# STM32G0C1 register map
File version: 1.0
CPU: CM0 r0p1, little endian, MPU, no FPU, 4 interrupt priority bits
Registers are 32-bit, read-write, reset 0x0 unless marked. A register's access mark holds for its fields unless they carry their own. Offsets are from the block's base; lines under a group give offsets from that group; [hi:lo] are bit positions; {n}, {i} and the like mark numbered series; 'fields as' and 'values as' point back to an identical list; <NAME> marks a mode.

## Memory map
0x40000000 TIM2 size 0x400 — General-purpose-timers
0x40000400 TIM3 size 0x400
0x40001000 TIM6 size 0x400 — Basic timers
0x40001400 TIM7 size 0x400
0x40002000 TIM14 size 0x400 — General purpose timers
0x40002C00 WWDG size 0x400 — System window watchdog
0x40003000 IWDG size 0x400 — Independent watchdog
0x40004400 USART2 size 0x400
0x40004800 USART3 size 0x400
0x40004C00 USART4 size 0x400
0x40005400 I2C1 size 0x400 — Inter-integrated circuit
0x40005800 I2C2 size 0x400
0x40007400 DAC size 0x400
0x40007800 HDMI_CEC size 0x400
0x40007C00 LPTIM1 size 0x400 — Low power timer
0x40009400 LPTIM2 size 0x400
0x40010030 VREFBUF size 0x400 — System configuration controller
0x40012C00 TIM1 size 0x400 — Advanced-timers
0x40013800 USART1 size 0x400 — Universal synchronous asynchronous receiver transmitter
0x40014000 TIM15 size 0x400 — General purpose timers
0x40014400 TIM16 size 0x400 — General purpose timers
0x40014800 TIM17 size 0x400
0x40020800 DMAMUX size 0x800
0x40023000 CRC size 0x400 — Cyclic redundancy check calculation unit

## Interrupts
0 WWDG — Window watchdog interrupt
11 DMA_Channel4_5_6_7 (DMAMUX) — DMA channel 4, 5, 6 & 7 and DMAMUX
13 TIM1_BRK_UP_TRG_COM (TIM1) — TIM1 break, update, trigger
14 TIM1_CC (TIM1) — TIM1 Capture Compare interrupt
15 TIM2 — TIM2 global interrupt
16 TIM3 — TIM3 global interrupt
17 TIM6_DAC (TIM6) — TIM6 + LPTIM1 and DAC global interrupt
18 TIM7 — TIM7 + LPTIM2 global interrupt
19 TIM14 — TIM14 global interrupt
20 TIM15 — Timer 15 global interrupt
21 TIM16 — TIM16 global interrupt
22 TIM17 — TIM17 global interrupt
23 I2C1 — I2C1 global interrupt
24 I2C2 — I2C2 global interrupt
27 USART1 — USART1 global interrupt
28 USART2 — USART2 global interrupt
29 USART3_USART4_LPUART1 (USART3) — USART3, USART4, and LPUART1 global interrupt
30 CEC (HDMI_CEC) — CEC global interrupt

## CRC — Cyclic redundancy check calculation unit
Base 0x40023000
0x00 CRC_DR reset 0xFFFFFFFF — Data register
  [31:0] DR — Data register bits
0x04 CRC_IDR — Independent data register
  [31:0] IDR — General-purpose 32-bit data register bits
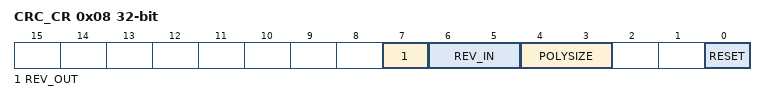
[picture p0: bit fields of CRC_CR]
0x08 CRC_CR access per field — Control register
  [7] REV_OUT rw — Reverse output data This bit controls the reversal of the bit order of the output data.
    0=Bit order not affected; 1=Bit-reversed output format
  [6:5] REV_IN rw — Reverse input data These bits control the reversal of the bit order of the input data
    0=Bit order not affected; 1=Bit reversal done by byte; 2=Bit reversal done by half-word; 3=Bit reversal done by word
  [4:3] POLYSIZE rw — Polynomial size These bits control the size of the polynomial.
    0=32 bit polynomial; 1=16 bit polynomial; 2=8 bit polynomial; 3=7 bit polynomial
  [0] RESET wo — RESET bit
0x10 CRC_INIT reset 0xFFFFFFFF — Initial CRC value
  [31:0] CRC_INIT — Programmable initial CRC value
0x14 CRC_POL reset 0x4C11DB7 — polynomial
  [31:0] POL — Programmable polynomial

## DMAMUX
Base 0x40020800
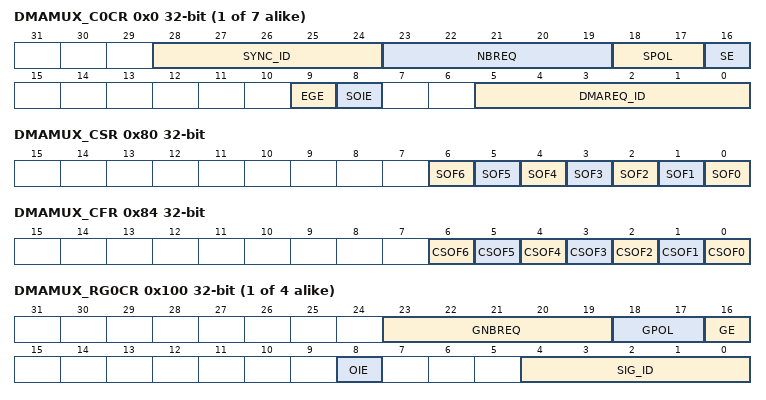
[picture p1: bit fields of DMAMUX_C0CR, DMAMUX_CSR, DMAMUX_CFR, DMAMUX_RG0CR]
{0x0+4i} DMAMUX_C{i}CR (i=0..6) — DMAMUX request line multiplexer channel x configuration register
  [28:24] SYNC_ID — Synchronization identification Selects the synchronization input (see inputs to resources STM32G0).
  [23:19] NBREQ — Number of DMA requests minus 1 to forward Defines the number of DMA requests to forward to the DMA controller after a synchronization event, and/or the number of DMA requests before an output event is generated. This field shall only be written when both SE and EGE bits are low.
  [18:17] SPOL — Synchronization polarity Defines the edge polarity of the selected synchronization input:
    0=no event, i.e. no synchronization nor detection.; 1=rising edge; 2=falling edge; 3=rising and falling edge
  [16] SE — Synchronization enable
    0=synchronization disabled; 1=synchronization enabled
  [9] EGE — Event generation enable
    0=event generation disabled; 1=event generation enabled
  [8] SOIE — Synchronization overrun interrupt enable
    0=interrupt disabled; 1=interrupt enabled
  [5:0] DMAREQ_ID — DMA request identification Selects the input DMA request. See the DMAMUX table about assignments of multiplexer inputs to resources.
0x80 DMAMUX_CSR ro — DMAMUX request line multiplexer interrupt channel status register
  [n] SOF{n} (n=0..6) — Synchronization overrun event flag The flag is set when a synchronization event occurs on a DMA request line multiplexer channel x, while the DMA request counter value is lower than NBREQ. The flag is cleared by writing 1 to the corresponding CSOFx bit in DMAMUX_CFR register.
0x84 DMAMUX_CFR wo — DMAMUX request line multiplexer interrupt clear flag register
  [n] CSOF{n} (n=0..6) — Clear synchronization overrun event flag Writing 1 in each bit clears the corresponding overrun flag SOFx in the DMAMUX_CSR register.
{0x100+4i} DMAMUX_RG{i}CR (i=0..3) — DMAMUX request generator channel x configuration register
  [23:19] GNBREQ — Number of DMA requests to be generated (minus 1) Defines the number of DMA requests to be generated after a trigger event. The actual number of generated DMA requests is GNBREQ +1. Note: This field shall only be written when GE bit is disabled.
  [18:17] GPOL — DMA request generator trigger polarity Defines the edge polarity of the selected trigger input
    0=no event. I.e. none trigger detection nor generation.; 1=rising edge; 2=falling edge; 3=rising and falling edge
  [16] GE — DMA request generator channel x enable
    0=DMA request generator channel x disabled; 1=DMA request generator channel x enabled
  [8] OIE — Trigger overrun interrupt enable
    0=interrupt on a trigger overrun event occurrence is disabled; 1=interrupt on a trigger overrun event occurrence is enabled
  [4:0] SIG_ID — Signal identification Selects the DMA request trigger input used for the channel x of the DMA request generator
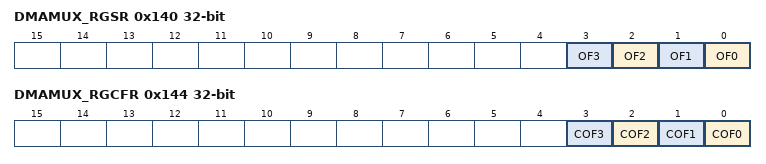
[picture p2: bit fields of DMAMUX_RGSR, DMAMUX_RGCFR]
0x140 DMAMUX_RGSR ro — DMAMUX request generator interrupt status register
  [n] OF{n} (n=0..3) — Trigger overrun event flag The flag is set when a new trigger event occurs on DMA request generator channel x, before the request counter underrun (the internal request counter programmed via the GNBREQ field of the DMAMUX_RGxCR register). The flag is cleared by writing 1 to the corresponding COFx bit in the DMAMUX_RGCFR register.
0x144 DMAMUX_RGCFR wo — DMAMUX request generator interrupt clear flag register
  [n] COF{n} (n=0..3) — Clear trigger overrun event flag Writing 1 in each bit clears the corresponding overrun flag OFx in the DMAMUX_RGSR register.
